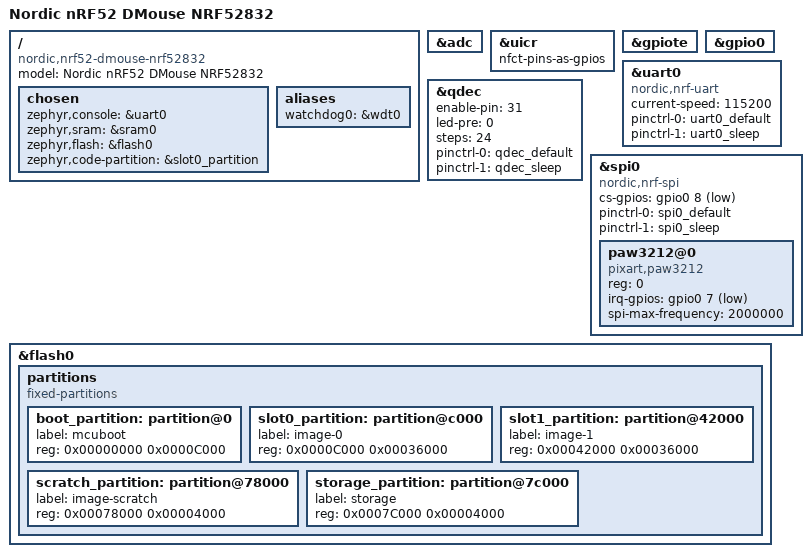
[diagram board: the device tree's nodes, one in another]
/*
 * Copyright (c) 2019-2022 Nordic Semiconductor ASA
 *
 * SPDX-License-Identifier: LicenseRef-Nordic-5-Clause
 */

/dts-v1/;
#include <nordic/nrf52832_qfaa.dtsi>
#include "nrf52dmouse_nrf52832-pinctrl.dtsi"

/ {
	model = "Nordic nRF52 DMouse NRF52832";
	compatible = "nordic,nrf52-dmouse-nrf52832";

	chosen {
		zephyr,console = &uart0;
		zephyr,sram = &sram0;
		zephyr,flash = &flash0;
		zephyr,code-partition = &slot0_partition;
	};

	/* These aliases are provided for compatibility with samples */
	aliases {
		watchdog0 = &wdt0;
	};
};

&adc {
	status = "okay";
};

&uicr {
	nfct-pins-as-gpios;
};

&gpiote {
	status = "okay";
};

&gpio0 {
	status = "okay";
};

&uart0 {
	status = "okay";
	compatible = "nordic,nrf-uart";
	current-speed = <115200>;
	pinctrl-0 = <&uart0_default>;
	pinctrl-1 = <&uart0_sleep>;
	pinctrl-names = "default", "sleep";
};

&qdec {
	status = "okay";
	enable-pin = <31>;
	led-pre = <0>;
	steps = <24>;
	pinctrl-0 = <&qdec_default>;
	pinctrl-1 = <&qdec_sleep>;
	pinctrl-names = "default", "sleep";
};

&spi0 {
	compatible = "nordic,nrf-spi";
	status = "okay";
	cs-gpios = <&gpio0 8 GPIO_ACTIVE_LOW>;

	pinctrl-0 = <&spi0_default>;
	pinctrl-1 = <&spi0_sleep>;
	pinctrl-names = "default", "sleep";
	paw3212@0 {
		compatible = "pixart,paw3212";
		reg = <0>;
		irq-gpios = <&gpio0 7 (GPIO_ACTIVE_LOW | GPIO_PULL_UP)>;
		spi-max-frequency = <2000000>;
	};
};

&flash0 {
	/*
	 * For more information, see:
	 * http://docs.zephyrproject.org/latest/guides/dts/index.html#flash-partitions
	 */
	partitions {
		compatible = "fixed-partitions";
		#address-cells = <1>;
		#size-cells = <1>;

		boot_partition: partition@0 {
			label = "mcuboot";
			reg = <0x00000000 0x0000C000>;
		};
		slot0_partition: partition@c000 {
			label = "image-0";
			reg = <0x0000C000 0x00036000>;
		};
		slot1_partition: partition@42000 {
			label = "image-1";
			reg = <0x00042000 0x00036000>;
		};
		scratch_partition: partition@78000 {
			label = "image-scratch";
			reg = <0x00078000 0x00004000>;
		};
		storage_partition: partition@7c000 {
			label = "storage";
			reg = <0x0007C000 0x00004000>;
		};
	};
};
